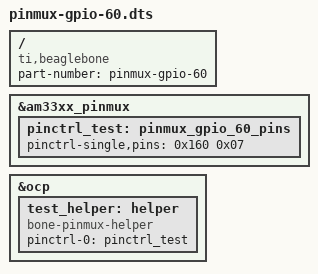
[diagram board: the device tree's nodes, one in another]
/* DM
*/

/dts-v1/;
/plugin/;

/{
       compatible = "ti,beaglebone", "ti,beaglebone-black";
       part-number = "pinmux-gpio-60";

       fragment@0 {
             target = <&am33xx_pinmux>;
            
             __overlay__ {
                  pinctrl_test: pinmux_gpio_60_pins {
			pinctrl-single,pins = <
				0x160 0x07  /* P9_12 muxRegOffset, OUTPUT MODE7 */
			>;
		  };
             };
       };

       fragment@1 {
		target = <&ocp>;
		__overlay__ {
			test_helper: helper {
				compatible = "bone-pinmux-helper";
				pinctrl-names = "default";
				pinctrl-0 = <&pinctrl_test>;
				status = "okay";
			};
		};
	};
};
